AUTOSAR XML (schema 4-3-0)
standard types defined: uint8, uint8_DataConstr
package /ComponentTypes/HkmcComponent/HkmcHbaAdap
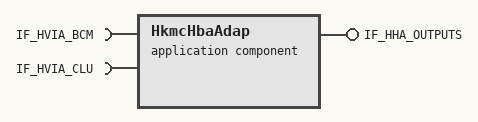
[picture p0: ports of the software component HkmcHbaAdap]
  application sw component type HkmcHbaAdap
    provide port IF_HHA_OUTPUTS: nonqueued-sender-com-spec=data-element=DE_HHA_OUTPUTS, provided-interface=IF_HHA_OUTPUTS
    require port IF_HVIA_BCM: nonqueued-receiver-com-spec{data-element=DE_HVIA_BCM, filter=data-filter-type=ALWAYS}, required-interface=IF_HVIA_BCM
    require port IF_HVIA_CLU: nonqueued-receiver-com-spec{data-element=DE_HVIA_CLU, filter=data-filter-type=ALWAYS}, required-interface=IF_HVIA_CLU
    behavior HkmcHbaAdap_InternalBehavior
  swc implementation HkmcHbaAdap_Implementation: behavior=HkmcHbaAdap_InternalBehavior
    code-descriptors:
      code Default: artifact-descriptors=autosar-engineering-object={short-label=Default, category=SWSRC}
package /ComponentTypes/HkmcComponent/HkmcHbaAdap/DataTypes
  impl type HHA_OUTPUTS_T: category=STRUCTURE, sw-calibration-access=READ-ONLY, type-emitter=RTE
    4 x element, all with category=TYPE_REFERENCE, implementation-data-type=uint8:
      HbaAdap_SysState: compu {0=Cx0_SysS_HBA_Disable, 1=Cx1_SysS_HBA_Enable_And_High_Beam_Off, 2=Cx2_SysS_HBA_Enable_And_High_Beam_On, 3=Cx3_SysS_Reserved, 4=Cx4_SysS_Reserved, 5=Cx5_SysS_Reserved, 6=Cx6_SysS_Reserved, 7=Cx7_SysS_System_Fail}
      HbaAdap_HBA_Opt: compu {0=Cx0_Opt_None_HBA_Option, 1=Cx1_Opt_HBA_Option, 2=Cx2_Opt_Reserved, 3=Cx3_Opt_Error_Indicator}
      HbaAdap_HBA_Lamp
      HbaAdap_HBA_Opt_USM: compu {0=Cx0_OptU_None_HBA_Option, 1=Cx1_OptU_HBA_Function_Off, 2=Cx2_OptU_HBA_Function_On, 3=Cx3_OptU_Invalid}
package /ComponentTypes/HkmcComponent/HkmcHbaAdap/PortInterfaces
  sender receiver interface IF_HHA_OUTPUTS: invalidation-policy{data-element=DE_HHA_OUTPUTS, handle-invalid=DONT-INVALIDATE}
    data DE_HHA_OUTPUTS: type=HHA_OUTPUTS_T
  sender receiver interface IF_HVIA_BCM: invalidation-policy{data-element=DE_HVIA_BCM, handle-invalid=DONT-INVALIDATE}
    data DE_HVIA_BCM: type=HVIA_BCM_T
  sender receiver interface IF_HVIA_CLU: invalidation-policy{data-element=DE_HVIA_CLU, handle-invalid=DONT-INVALIDATE}
    data DE_HVIA_CLU: type=HVIA_CLU_T
package /ComponentTypes/HkmcComponent/HkmcVehicleInputAdap/DataTypes
  impl type HVIA_BCM_T: category=STRUCTURE, sw-calibration-access=READ-ONLY, type-emitter=RTE
    element HkmcVehInput_HBA_ControlMode: compu {0=Cx0_ContM_HighControlMode_BCM, 1=Cx1_ContM_HighControlMode_HBA, 2=Cx2_ContM_Not_Used, 3=Cx3_ContM_Error_Indicator}, implementation-data-type=uint8
  impl type HVIA_CLU_T: category=STRUCTURE, sw-calibration-access=READ-ONLY, type-emitter=RTE
    5 x element, all with category=TYPE_REFERENCE, implementation-data-type=uint8:
      HkmcVehicleInput_SpdUnitTyp: compu {0=Cx0_SpdUT_kmperh, 1=Cx1_SpdUT_MPH, 2=Cx2_SpdUT_Not_used, 3=Cx3_SpdUT_Error_Indicator}
      HkmcVehicleInput_Fca1stWrngSetReq: compu {0=Cx0_Fca1stWSR_Default, 1=Cx1_Fca1stWSR_LDW_Mode, 2=Cx2_Fca1stWSR_LKA_Mode, 3=Cx3_Fca1stWSR_Reserved, 4=Cx4_Fca1stWSR_Reserved, 5=Cx5_Fca1stWSR_Reserved, 6=Cx6_Fca1stWSR_Reserved, 7=Cx7_Fca1stWSR_Invalid}
      HkmcVehicleInput_AdasFCASetReq: compu {0=Cx0_AdasFCASR_Default, 1=Cx1_AdasFCASR_Off, 2=Cx2_AdasFCASR_Warning, 3=Cx3_AdasFCASR_Assist, 4=Cx4_AdasFCASR_Reserved, 5=Cx5_AdasFCASR_Reserved, 6=Cx6_AdasFCASR_Reserved, 7=Cx7_AdasFCASR_Invalid}
      HkmcVehicleInput_LkaModSetReq: compu {0=Cx0_LkaModSR_Default, 1=Cx1_LkaModSR_LDW_mode, 2=Cx2_LkaModSR_LKA_mode, 3=Cx3_LkaModSR_ACTIVE_LKA, 4=Cx4_LkaModSR_LDW_ON, 5=Cx5_LkaModSR_LDW_OFF, 6=Cx6_LkaModSR_LDW_LKA_OFF, 7=Cx7_LkaModSR_Invalid}
      HkmcVehInput_HBA_NValueSet: compu {0=Cx0_NVS_Default, 1=Cx1_NVS_HBA_Off, 2=Cx2_NVS_HBA_On, 3=Cx3_NVS_Invalid}
